# rac_gccp register map
Vendor: Texas Instruments
Peripheral module from a debugger description file (folder Keystone2).
Registers are 32-bit, read-write, no defined reset value unless marked. A register's access mark holds for its fields unless they carry their own. Offsets are as the file gives them; lines under a group give offsets from that group; [hi:lo] are bit positions; {n}, {i} and the like mark numbered series; 'fields as' and 'values as' point back to an identical list; <NAME> marks a mode.

## RAC_3_GCCP1
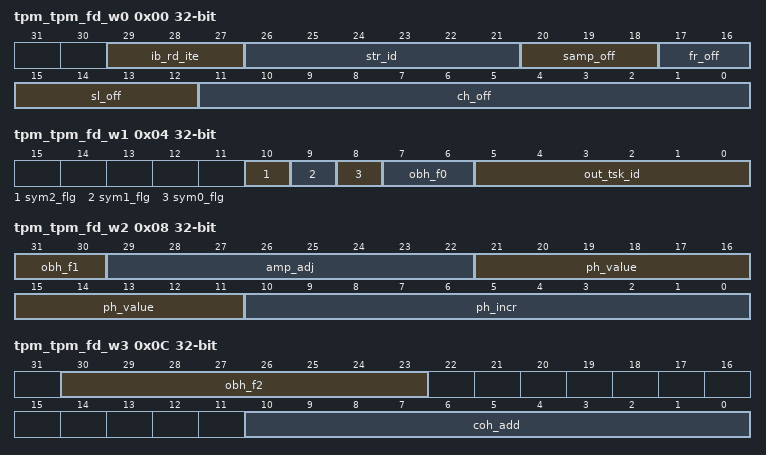
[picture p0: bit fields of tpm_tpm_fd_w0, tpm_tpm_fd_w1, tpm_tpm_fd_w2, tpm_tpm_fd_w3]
0x00 tpm_tpm_fd_w0 — (1 of 3072, stride 16)
  [29:27] ib_rd_ite, [26:21] str_id, [20:18] samp_off, [17:16] fr_off, [15:12] sl_off, [11:0] ch_off
0x04 tpm_tpm_fd_w1 — (1 of 3072, stride 16)
  [10] sym2_flg, [9] sym1_flg, [8] sym0_flg, [7:6] obh_f0, [5:0] out_tsk_id
0x08 tpm_tpm_fd_w2 — (1 of 3072, stride 16)
  [31:30] obh_f1, [29:22] amp_adj, [21:11] ph_value, [10:0] ph_incr
0x0C tpm_tpm_fd_w3 — (1 of 3072, stride 16)
  [30:23] obh_f2, [10:0] coh_add
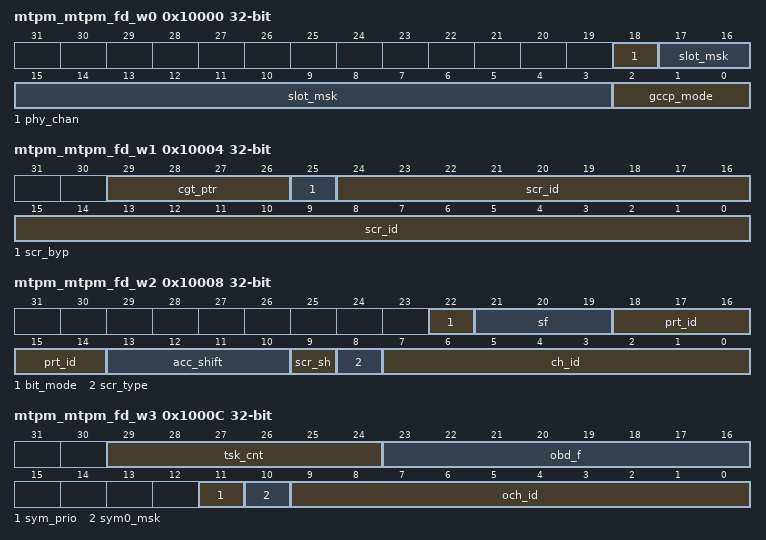
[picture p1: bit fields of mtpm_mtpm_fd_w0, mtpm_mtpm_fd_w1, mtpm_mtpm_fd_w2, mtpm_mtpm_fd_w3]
0x10000 mtpm_mtpm_fd_w0 — (1 of 768, stride 32)
  [18] phy_chan, [17:3] slot_msk, [2:0] gccp_mode
0x10004 mtpm_mtpm_fd_w1 — (1 of 768, stride 32)
  [29:26] cgt_ptr, [25] scr_byp, [24:0] scr_id
0x10008 mtpm_mtpm_fd_w2 — (1 of 768, stride 32)
  [22] bit_mode, [21:19] sf, [18:14] prt_id, [13:10] acc_shift, [9] scr_sh, [8] scr_type, [7:0] ch_id
0x1000C mtpm_mtpm_fd_w3 — (1 of 768, stride 32)
  [29:24] tsk_cnt, [23:16] obd_f, [11] sym_prio, [10] sym0_msk, [9:0] och_id
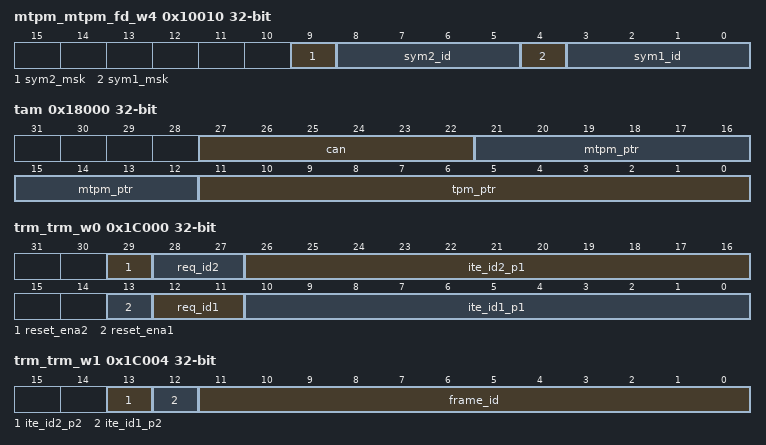
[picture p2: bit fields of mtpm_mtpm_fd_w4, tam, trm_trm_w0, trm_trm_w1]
0x10010 mtpm_mtpm_fd_w4 — (1 of 768, stride 32)
  [9] sym2_msk, [8:5] sym2_id, [4] sym1_msk, [3:0] sym1_id
0x18000 tam — (1 of 3072, stride 4)
  [27:22] can, [21:12] mtpm_ptr, [11:0] tpm_ptr
0x1C000 trm_trm_w0 — (1 of 1536, stride 8)
  [29] reset_ena2, [28:27] req_id2, [26:16] ite_id2_p1, [13] reset_ena1, [12:11] req_id1, [10:0] ite_id1_p1
0x1C004 trm_trm_w1 — (1 of 1536, stride 8)
  [13] ite_id2_p2, [12] ite_id1_p2, [11:0] frame_id
0x1F000 gccp_seq_ena
  [0] enable
0x1F004 gccp_seq_act
  [11:0] act_count
0x1F008 gccp_seq_cyc
  [11:0] seq_count
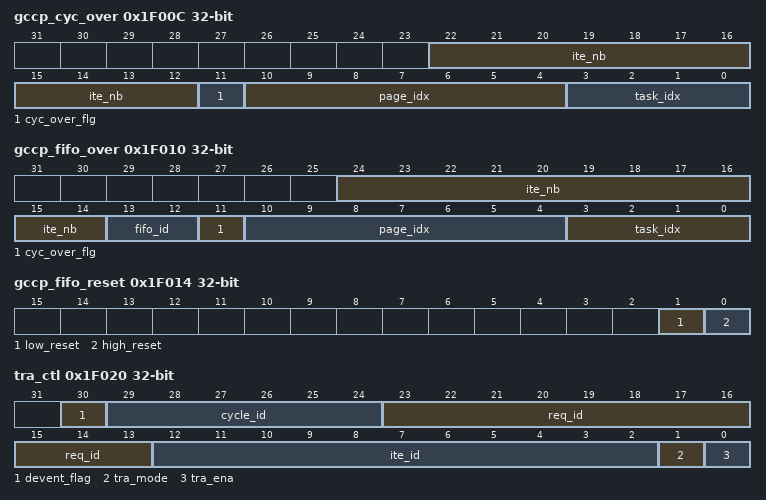
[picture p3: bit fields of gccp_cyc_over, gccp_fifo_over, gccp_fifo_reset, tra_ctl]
0x1F00C gccp_cyc_over
  [22:12] ite_nb, [11] cyc_over_flg, [10:4] page_idx, [3:0] task_idx
0x1F010 gccp_fifo_over
  [24:14] ite_nb, [13:12] fifo_id, [11] cyc_over_flg, [10:4] page_idx, [3:0] task_idx
0x1F014 gccp_fifo_reset
  [1] low_reset, [0] high_reset
0x1F018 gccp_rd_sys_time access not given
0x1F020 tra_ctl
  [30] devent_flag, [29:24] cycle_id, [23:13] req_id, [12:2] ite_id, [1] tra_mode, [0] tra_ena
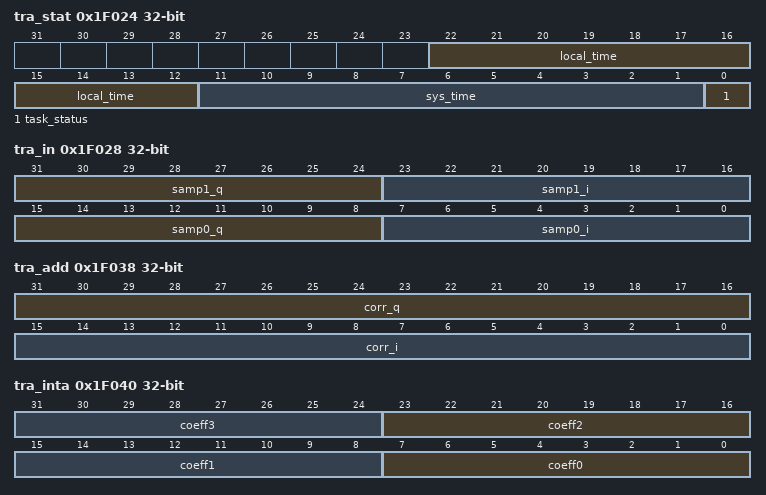
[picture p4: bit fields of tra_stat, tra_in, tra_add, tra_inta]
0x1F024 tra_stat
  [22:12] local_time, [11:1] sys_time, [0] task_status
0x1F028 tra_in — (1 of 2, stride 4)
  [31:24] samp1_q, [23:16] samp1_i, [15:8] samp0_q, [7:0] samp0_i
0x1F030 tra_ref — (1 of 2, stride 4)
  [31:0] ref_code
0x1F038 tra_add — (1 of 2, stride 4)
  [31:16] corr_q, [15:0] corr_i
0x1F040 tra_inta
  [8n+7:8n] coeff{n} (n=0..3)
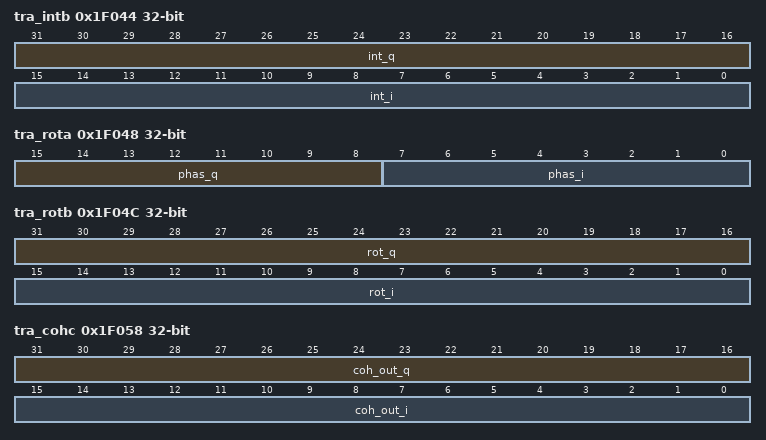
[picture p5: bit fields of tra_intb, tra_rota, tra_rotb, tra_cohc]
0x1F044 tra_intb
  [31:16] int_q, [15:0] int_i
0x1F048 tra_rota
  [15:8] phas_q, [7:0] phas_i
0x1F04C tra_rotb
  [31:16] rot_q, [15:0] rot_i
0x1F050 tra_coh — (1 of 2, stride 4)
  [31:0] coh_acc
0x1F058 tra_cohc
  [31:16] coh_out_q, [15:0] coh_out_i
0x1F05C tra_amp
  [15:0] amplitude
0x1F060 tra_ncoh
  [15:0] ncoh_acc
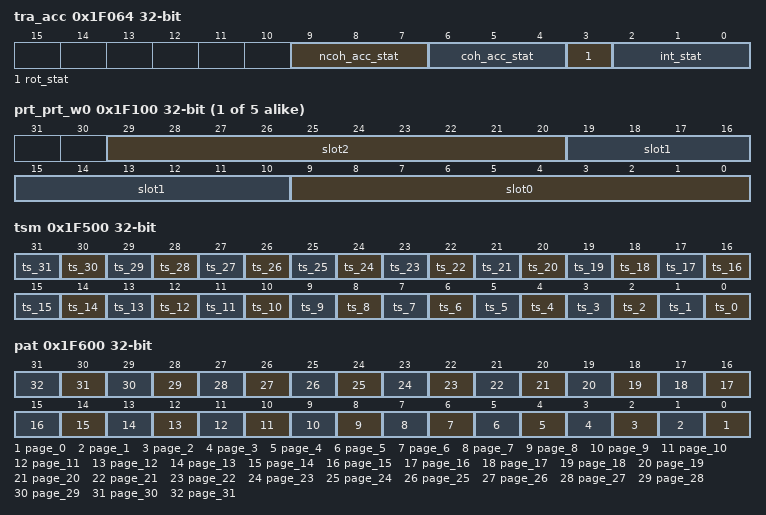
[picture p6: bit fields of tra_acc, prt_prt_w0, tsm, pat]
0x1F064 tra_acc
  [9:7] ncoh_acc_stat, [6:4] coh_acc_stat, [3] rot_stat, [2:0] int_stat
0x1F068 tra_tpm — (1 of 4, stride 4)
  [31:0] word
0x1F078 tra_mtpm — (1 of 5, stride 4)
  [31:0] word
{0x1F100+4i} prt_prt_w{i} (i=0..4) — (1 of 24, stride 32)
  [29:20] slot{3i+2}, [19:10] slot{3i+1}, [9:0] slot{3i}
0x1F500 tsm — (1 of 48, stride 4)
  [n] ts_{n} (n=0..31)
0x1F600 pat — (1 of 3, stride 4)
  [n] page_{n} (n=0..31)
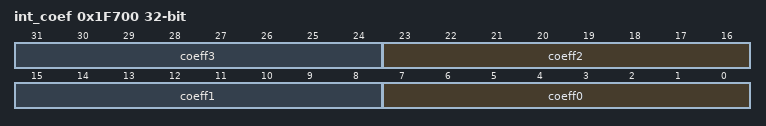
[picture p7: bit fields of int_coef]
0x1F700 int_coef — (1 of 5, stride 4)
  [8n+7:8n] coeff{n} (n=0..3)
0x1F800 hcq_curr_lvl
  [7:0] curr_lvl
0x1F804 hcq_wtmk_lvl
  [7:0] watermark
0x1F808 hdq_curr_lvl
  [7:0] curr_lvl
0x1F80C hdq_wtmk_lvl
  [7:0] watermark
0x1F810 lcq_curr_lvl
  [10:0] curr_lvl
0x1F814 lcq_wtmk_lvl
  [10:0] watermark
0x1F818 ldq_curr_lvl
  [11:0] curr_lvl
0x1F81C ldq_wtmk_lvl
  [11:0] watermark
0x1F900 cgt — (1 of 16, stride 4)
  [24:0] y_part
